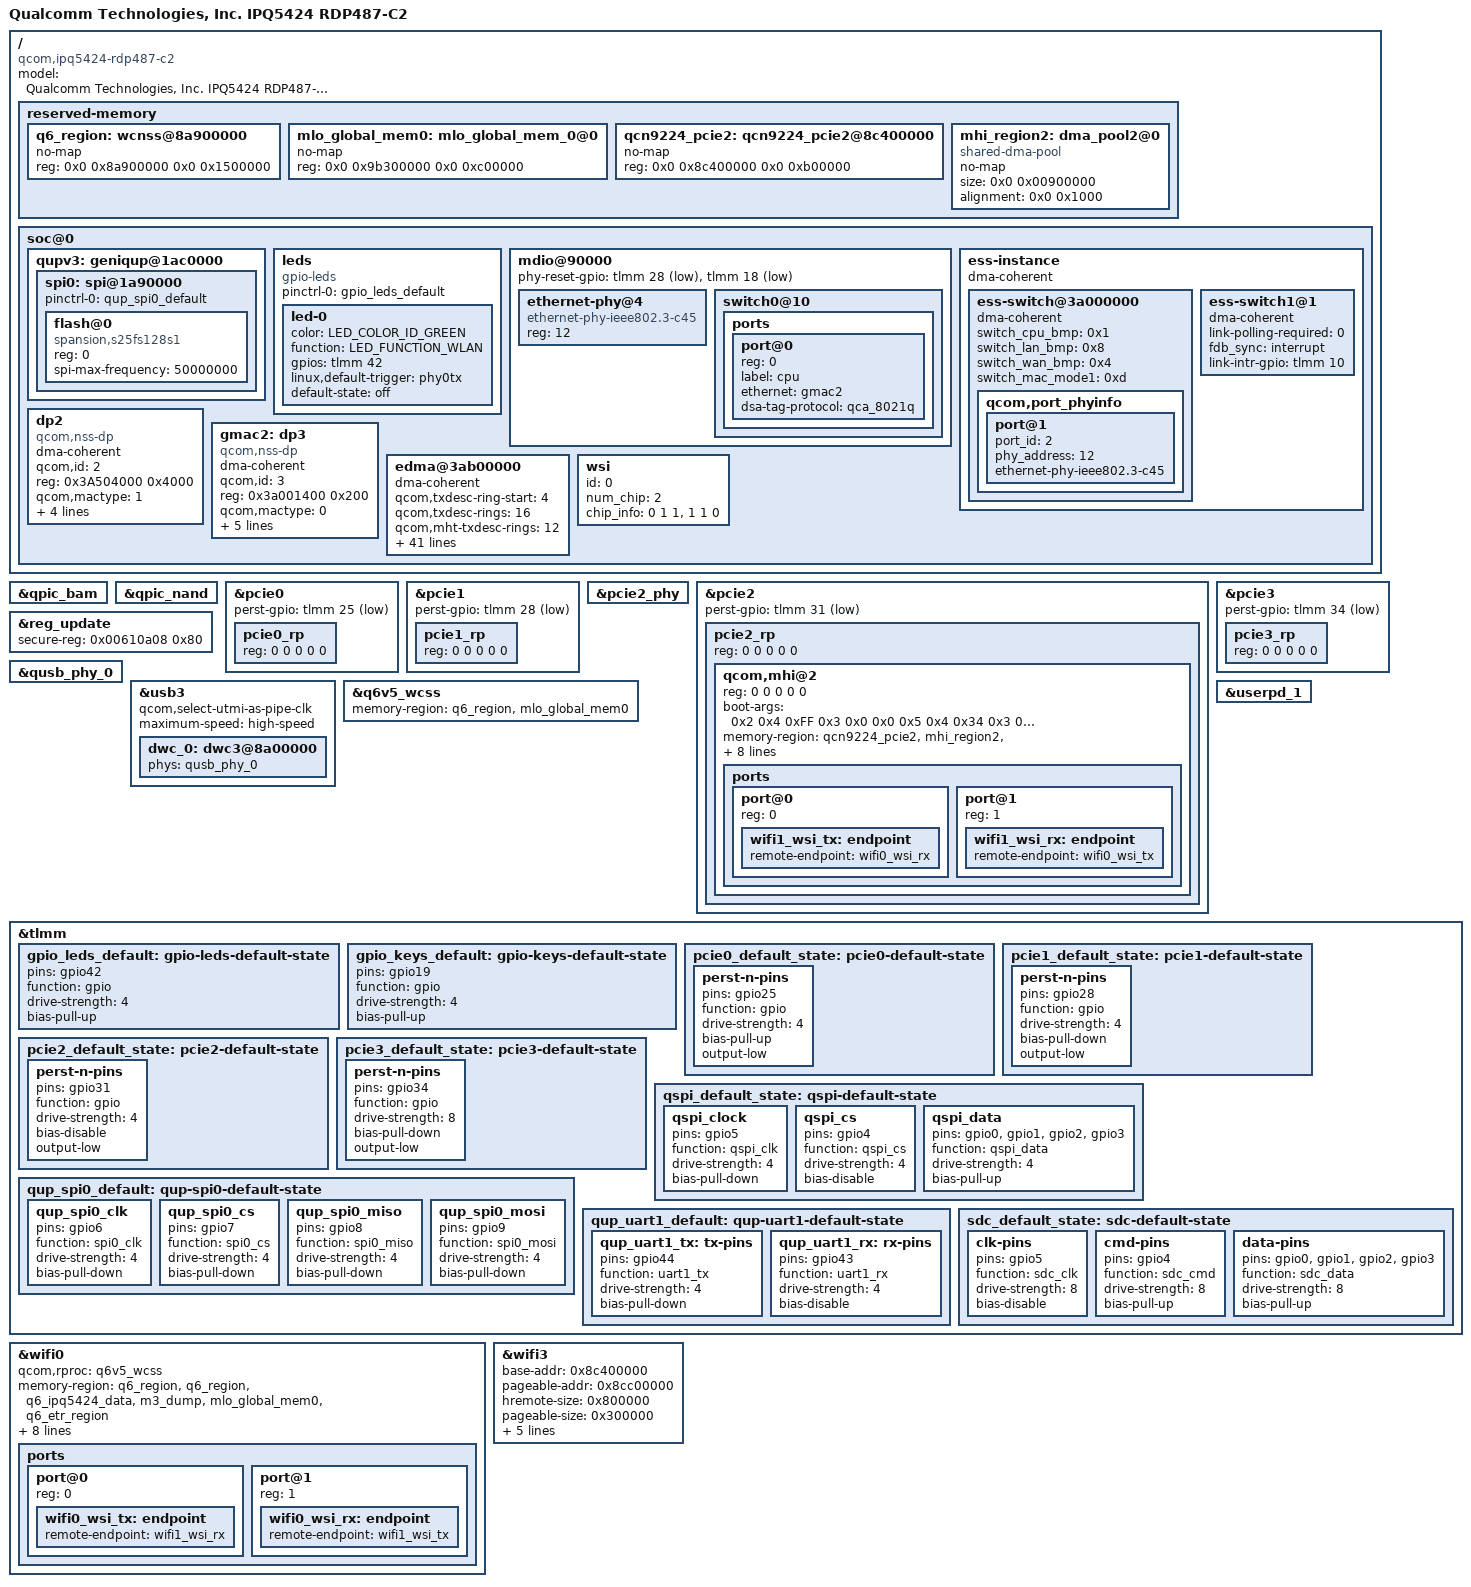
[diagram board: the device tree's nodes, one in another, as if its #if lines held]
// SPDX-License-Identifier: (GPL-2.0+ OR BSD-3-Clause)
/*
 * IPQ5424 RDP487-C2 board device tree source
 *
 * Copyright (c) 2020-2021 The Linux Foundation. All rights reserved.
 * Copyright (c) Qualcomm Technologies, Inc. and/or its subsidiaries.
 */

/dts-v1/;

#include "ipq5424-rdp-common.dtsi"
#if defined(__IPQ_MEM_PROFILE_512_MB__)
#include "ipq5424-512MB-default-memory.dtsi"
#elif !defined(__IPQ_MEM_PROFILE_256_MB__)
#include "ipq5424-default-memory.dtsi"
#endif

/ {
	model = "Qualcomm Technologies, Inc. IPQ5424 RDP487-C2";
	compatible = "qcom,ipq5424-rdp487-c2", "qcom,ipq5424";

#ifdef __IPQ_MEM_PROFILE_256_MB__
	/*                    256MB Profile
	 * +==========+==============+========================+
	 * |         |              |                         |
	 * |  Region | Start Offset |          Size           |
	 * |         |              |                         |
	 * +---------+--------------+-------------------------+
	 * |         |              |                         |
	 * |   WLAN  |              |                         |
	 * |    Q6   |  0x8a900000  |          21MB           |
	 * |         |              |                         |
	 * +---------+--------------+-------------------------+
	 * |         |              |                         |
	 * |  MLO    |  0x8bf00000  |          5MB            |
	 * |         |              |                         |
	 * +---------+--------------+-------------------------+
	 * |         |              |                         |
	 * | QCN9224 |  0x8c400000  |          11MB           |
	 * | PCIE0   |              |                         |
	 * |         |              |                         |
	 * +---------+--------------+-------------------------+
	 * |         |              |                         |
	 * |  MHI0   |    DYNAMIC   |          9MB            |
	 * |         |              |                         |
	 * +==================================================+
	 * |                                                  |
	 * |                                                  |
	 * |                                                  |
	 * |             Rest of memory for Linux             |
	 * |                                                  |
	 * |                                                  |
	 * |                                                  |
	 * +==================================================+
	 */

	reserved-memory {
		#address-cells = <2>;
		#size-cells = <2>;
		ranges;

		q6_region: wcnss@8a900000 {
			no-map;
			reg = <0x0 0x8a900000 0x0 0x1500000>;
		};

		mlo_global_mem0: mlo_global_mem_0@0 {
			no-map;
			reg = <0x0 0x8bf00000 0x0 0x500000>;
		};

		qcn9224_pcie2: qcn9224_pcie2@8c400000 {
			no-map;
			reg = <0x0 0x8c400000 0x0 0xb00000>;
		};

		mhi_region2: dma_pool2@0 {
			compatible = "shared-dma-pool";
			no-map;
			size = <0x0 0x00900000>;
			alignment = <0x0 0x1000>;
		};

	};
#endif

	soc@0 {
		qupv3: geniqup@1ac0000 {

			spi0: spi@1a90000 {
				pinctrl-0 = <&qup_spi0_default>;
				pinctrl-names = "default";
				status = "okay";

				flash@0 {
					compatible = "spansion,s25fs128s1", "jedec,spi-nor";
					#address-cells = <1>;
					#size-cells = <1>;
					reg = <0>;
					spi-max-frequency = <50000000>;
				};
			};
		};

		leds {
			compatible = "gpio-leds";
			pinctrl-0 = <&gpio_leds_default>;
			pinctrl-names = "default";

			led-0 {
				color = <LED_COLOR_ID_GREEN>;
				function = LED_FUNCTION_WLAN;
				gpios = <&tlmm 42 GPIO_ACTIVE_HIGH>;
				linux,default-trigger = "phy0tx";
				default-state = "off";
			};
		};

		mdio@90000 {
			/* GPIO28 is for port 2 QCA81XX PHY */
			/* GPIO18 is for QCA8386 switch */
			phy-reset-gpio = <
				&tlmm 28 GPIO_ACTIVE_LOW
				&tlmm 18 GPIO_ACTIVE_LOW
			>;

			ethernet-phy@4 {
				reg = <12>;
				compatible ="ethernet-phy-ieee802.3-c45";
			};

			switch0@10 {
				ports {
					port@0 {
						reg = <0>;
						label = "cpu";
						ethernet = <&gmac2>;
						dsa-tag-protocol = "qca_8021q";
					};
				};
			};
		};

		ess-instance {
#ifdef __CONFIG_IO_COHERENCY__
			dma-coherent;
#endif
			ess-switch@3a000000 {
#ifdef __CONFIG_IO_COHERENCY__
				dma-coherent;
#endif
				switch_cpu_bmp = <0x1>;  /* cpu port bitmap */
				switch_lan_bmp = <0x8>; /* lan port bitmap */
				switch_wan_bmp = <0x4>; /* wan port bitmap */
				switch_mac_mode1 = <0xd>; /* mac mode for uniphy instance1*/

				qcom,port_phyinfo {
					port@1 {
						port_id = <2>;
						phy_address = <12>;
						ethernet-phy-ieee802.3-c45;
					};
				};
			};

			ess-switch1@1 {
#ifdef __CONFIG_IO_COHERENCY__
				dma-coherent;
#endif
				link-polling-required = <0>;
				fdb_sync = "interrupt";
				link-intr-gpio = <&tlmm 10 GPIO_ACTIVE_HIGH>;
			};
		};

		dp2 {
			device_type = "network";
			compatible = "qcom,nss-dp";
#ifdef __CONFIG_IO_COHERENCY__
			dma-coherent;
#endif
			qcom,id = <2>;
			reg = <0x3A504000 0x4000>;
			qcom,mactype = <1>;
			local-mac-address = [000000000000];
			qcom,phy-mdio-addr = <12>;
			qcom,link-poll = <1>;
			phy-mode = "usxgmii";
		};

		gmac2:dp3 {
			device_type = "network";
			compatible = "qcom,nss-dp";
#ifdef __CONFIG_IO_COHERENCY__
			dma-coherent;
#endif
			qcom,id = <3>;
			reg = <0x3a001400 0x200>;
			qcom,mactype = <0>;
			local-mac-address = [000000000000];
			qcom,mht-dev = <1>;
			qcom,is_switch_connected = <1>;
			phy-mode = "sgmii";
			qcom,ppe-offload-disabled = <1>;
		};

		/* EDMA host driver configuration for the board */
		edma@3ab00000 {
#ifdef __CONFIG_IO_COHERENCY__
			dma-coherent;
#endif
			qcom,txdesc-ring-start = <4>;		/* Tx desc ring start ID */
			qcom,txdesc-rings = <16>;		/* Total number of Tx desc rings to be provisioned */
			qcom,mht-txdesc-rings = <12>;		/* Extra Tx desc rings to be provisioned for MHT SW ports */
			qcom,txcmpl-ring-start = <4>;		/* Tx complete ring start ID */
			qcom,txcmpl-rings = <16>;		/* Total number of Tx complete rings to be provisioned */
			qcom,mht-txcmpl-rings = <12>;		/* Extra Tx complete rings to be provisioned for mht sw ports. */
			qcom,rxfill-ring-start = <4>;		/* Rx fill ring start ID */
			qcom,rxfill-rings = <4>;		/* Total number of Rx fill rings to be provisioned */
			qcom,rxdesc-ring-start = <20>;		/* Rx desc ring start ID */
			qcom,rxdesc-rings = <4>;		/* Total number of Rx desc rings to be provisioned */
			qcom,rx-page-mode = <0>;		/* Rx fill ring page mode */
			qcom,tx-map-priority-level = <1>;	/* Tx priority level per port */
			qcom,rx-map-priority-level = <1>;	/* Rx priority level per core */
			qcom,ppeds-num = <3>;			/* Number of PPEDS nodes */
			/* PPE-DS node format: <Rx-fill Tx-cmpl Rx Tx Queue-base Queue-count> */
			qcom,ppeds-map = <1 1 1 1 32 8>,	/* PPEDS Node #0 ring and queue map */
					<2 2 2 2 40 8>,		/* PPEDS Node #1 ring and queue map */
					<3 3 3 3 48 8>;		/* PPEDS Node #2 ring and queue map */
			qcom,txdesc-map = <4 5 6 7>,		/* Port1 per-core Tx ring map */
					<8 9 10 11>,		/* Port2 per-core Tx ring map */
					<12 13 14 15>,		/* MHT-Port1 per-core Tx ring map */
					<16 17 18 19>,		/* MHT-Port2 per-core Tx ring map */
					<20 21 22 23>,		/* MHT-Port3 per-core Tx ring map */
					<24 25 26 27>,		/* MHT-Port4 per-core Tx ring map */
					<28 29 30 31>;		/* Used only for packets from VP */
			qcom,txdesc-fc-grp-map = <1 2 3 4 5 6>;	/* Per GMAC flow control group map */
			qcom,rxfill-map = <4 5 6 7>;		/* Per-core Rx fill ring map */
			qcom,rxdesc-map = <20 21 22 23>;	/* Per-core Rx desc ring map */
			qcom,rx-queue-start = <0>;		/* Rx queue start */
			qcom,edma_loopback_ring;                /* Enable Loopback ring */
			qcom,num_loopback_rings = <1>;          /* Number of loopback rings */
			qcom,txdesc_loopback_ring_id = <0>;     /* Loopback TX desc ring ID */
			qcom,txcmpl_loopback_ring_id = <0>;     /* Loopback TX cmpl ring ID */
			qcom,rxfill_loopback_ring_id = <0>;     /* Loopback RX fill ring ID */
			qcom,rxdesc_loopback_ring_id = <0>;     /* Loopback RX desc ring ID */
			qcom,loopback_queue_base = <56>;        /* Loopback queue base */
			qcom,loopback_num_queues = <8>;         /* Number of Loopback queues */
			qcom,rx-ring-queue-map = <0 8 16 24>,	/* Priority 0 queues per-core Rx ring map */
						<1 9 17 25>,	/* Priority 1 queues per-core Rx ring map */
						<2 10 18 26>,	/* Priority 2 queues per-core Rx ring map */
						<3 11 19 27>,	/* Priority 3 queues per-core Rx ring map */
						<4 12 20 28>,	/* Priority 4 queues per-core Rx ring map */
						<5 13 21 29>,	/* Priority 5 queues per-core Rx ring map */
						<6 14 22 30>,	/* Priority 6 queues per-core Rx ring map */
						<7 15 23 31>;	/* Priority 7 queues per-core Rx ring map */
			interrupts = <0 286 4>,			/* Tx complete ring id #4 IRQ info */
					<0 287 4>,		/* Tx complete ring id #5 IRQ info */
					<0 288 4>,		/* Tx complete ring id #6 IRQ info */
					<0 289 4>,		/* Tx complete ring id #7 IRQ info */
					<0 290 4>,		/* Tx complete ring id #8 IRQ info */
					<0 291 4>,		/* Tx complete ring id #9 IRQ info */
					<0 292 4>,		/* Tx complete ring id #10 IRQ info */
					<0 293 4>,		/* Tx complete ring id #11 IRQ info */
					<0 294 4>,		/* Tx complete ring id #12 IRQ info */
					<0 295 4>,		/* Tx complete ring id #13 IRQ info */
					<0 296 4>,		/* Tx complete ring id #14 IRQ info */
					<0 297 4>,		/* Tx complete ring id #15 IRQ info */
					<0 298 4>,		/* Tx complete ring id #16 IRQ info */
					<0 299 4>,		/* Tx complete ring id #17 IRQ info */
					<0 300 4>,		/* Tx complete ring id #18 IRQ info */
					<0 301 4>,		/* Tx complete ring id #19 IRQ info */
					<0 270 4>,		/* Rx desc ring id #20 IRQ info */
					<0 271 4>,		/* Rx desc ring id #21 IRQ info */
					<0 272 4>,		/* Rx desc ring id #22 IRQ info */
					<0 273 4>,		/* Rx desc ring id #23 IRQ info */
					<0 314 4>,		/* Misc error IRQ info */
					<0 278 4>,		/* RxFill ring id #4 IRQ info */
					<0 279 4>,		/* RxFill ring id #5 IRQ info */
					<0 280 4>,		/* RxFill ring id #6 IRQ info */
					<0 281 4>,		/* RxFill ring id #7 IRQ info */
					<0 283 4>,		/* PPEDS Node #0(TxComp ring id #1) TxComplete IRQ info */
					<0 251 4>,		/* PPEDS Node #0(Rx Desc ring id #1) Rx Desc IRQ info */
					<0 275 4>,		/* PPEDS Node #0(RxFill Desc ring id #1) Rx Fill IRQ info */
					<0 284 4>,		/* PPEDS Node #1(TxComp ring id #2) TxComplete IRQ info */
					<0 252 4>,		/* PPEDS Node #1(Rx Desc ring id #2) Rx Desc IRQ info */
					<0 276 4>,		/* PPEDS Node #1(RxFill Desc ring id #2) Rx Fill IRQ info */
					<0 285 4>,		/* PPEDS Node #2(TxComp ring id #3) TxComplete IRQ info */
					<0 253 4>,		/* PPEDS Node #2(Rx Desc ring id #3) Rx Desc IRQ info */
					<0 277 4>,		/* PPEDS Node #2(RxFill Desc ring id #3) Rx Fill IRQ info */
					<0 302 4>,		/* MHT port Tx complete ring id #20 IRQ info */
					<0 303 4>,		/* MHT port Tx complete ring id #21 IRQ info */
					<0 304 4>,		/* MHT port Tx complete ring id #22 IRQ info */
					<0 305 4>,		/* MHT port Tx complete ring id #23 IRQ info */
					<0 306 4>,		/* MHT port Tx complete ring id #24 IRQ info */
					<0 307 4>,		/* MHT port Tx complete ring id #25 IRQ info */
					<0 308 4>,		/* MHT port Tx complete ring id #26 IRQ info */
					<0 309 4>,		/* MHT port Tx complete ring id #27 IRQ info */
					<0 310 4>,		/* MHT port Tx complete ring id #28 IRQ info */
					<0 311 4>,		/* MHT port Tx complete ring id #29 IRQ info */
					<0 312 4>,		/* MHT port Tx complete ring id #30 IRQ info */
					<0 313 4>;		/* MHT port Tx complete ring id #31 IRQ info */
		};

		wsi: wsi {
			id = <0>;
			num_chip = <2>;
			chip_info = <0 1 1>,
				    <1 1 0>;
			status = "okay";
		};
	};
};

&qpic_bam {
	status = "okay";
};

&qpic_nand {
	status = "okay";
};

&pcie0 {
	perst-gpio = <&tlmm 25 GPIO_ACTIVE_LOW>;

	pcie0_rp {
		reg = <0 0 0 0 0>;
	};
};

&pcie1 {
	perst-gpio = <&tlmm 28 GPIO_ACTIVE_LOW>;

	pcie1_rp {
		reg = <0 0 0 0 0>;
	};
};

&pcie2_phy {
	status = "okay";
};

&pcie2 {
	status = "okay";
	perst-gpio = <&tlmm 31 GPIO_ACTIVE_LOW>;

	pcie2_rp {
		reg = <0 0 0 0 0>;

		qcom,mhi@2 {
			reg = <0 0 0 0 0>;
			boot-args = <0x2 0x4 0xFF 0x3 0x0 0x0  /* MX Rail, Invalid GPIO, Drive strength 0x3 */
					0x5 0x4 0x34 0x3 0x0 0x16 /* CX Rail, GPIO52, Drive strength 0x3, CPR1_fuse 0x0, CPR0_fuse 0x16 */
					0x0 0x4 0x0 0x0 0x0 0x0>; /* End of arguments */
			memory-region = <&qcn9224_pcie2>, <&mhi_region2>, <&mlo_global_mem0>;
			memory-region-names = "host-ddr-mem", "mhi-region", "mlo-global-mem";
			qcom,early_cal_enabled = "supported";
			qcom,caldata_offset = <0x12000>;
			qcom,board_id = <0x33>;
			qcom,wsi = <&wsi>;
			qcom,wsi_index = <1>;
			ports {
				#address-cells = <1>;
				#size-cells = <0>;

				port@0 {
					reg = <0>;

					wifi1_wsi_tx: endpoint {
						remote-endpoint = <&wifi0_wsi_rx>;
					};
				};

				port@1 {
					reg = <1>;

					wifi1_wsi_rx: endpoint {
						remote-endpoint = <&wifi0_wsi_tx>;
					};
				};
			};
		};
	};
};

&pcie3 {
	perst-gpio = <&tlmm 34 GPIO_ACTIVE_LOW>;

	pcie3_rp {
		reg = <0 0 0 0 0>;
	};
};

&reg_update {
	secure-reg = <0x00610a08 0x80>; /* aggr_noc_pcie2 */
};

&qusb_phy_0 {
	status = "okay";
};

&usb3 {
	status = "okay";
	qcom,select-utmi-as-pipe-clk;
	maximum-speed = "high-speed";

	dwc_0: dwc3@8a00000 {
		phys = <&qusb_phy_0>;
		phy-names = "usb2-phy";
	};
};

&q6v5_wcss {
#ifdef __IPQ_MEM_PROFILE_256_MB__
	memory-region = <&q6_region>,
			<&mlo_global_mem0>;
#endif
	status = "okay";
};

#if !defined(__RPROC_DISABLE_MPD_SUPPORT__)
&userpd_1 {
	status = "okay";
};
#endif

&tlmm {
	gpio_leds_default: gpio-leds-default-state {
		pins = "gpio42";
		function = "gpio";
		drive-strength = <4>;
		bias-pull-up;
	};

	gpio_keys_default: gpio-keys-default-state {
		pins = "gpio19";
		function = "gpio";
		drive-strength = <4>;
		bias-pull-up;
	};

	pcie0_default_state: pcie0-default-state {
		perst-n-pins {
			pins = "gpio25";
			function = "gpio";
			drive-strength = <4>;
			bias-pull-up;
			output-low;
		};
	};

	pcie1_default_state: pcie1-default-state {
		perst-n-pins {
			pins = "gpio28";
			function = "gpio";
			drive-strength = <4>;
			bias-pull-down;
			output-low;
		};
	};

	pcie2_default_state: pcie2-default-state {
		perst-n-pins {
			pins = "gpio31";
			function = "gpio";
			drive-strength = <4>;
			bias-disable;
			output-low;
		};
	};

	pcie3_default_state: pcie3-default-state {
		perst-n-pins {
			pins = "gpio34";
			function = "gpio";
			drive-strength = <8>;
			bias-pull-down;
			output-low;
		};
	};

	qspi_default_state: qspi-default-state {
		qspi_clock {
			pins = "gpio5";
			function = "qspi_clk";
			drive-strength = <4>;
			bias-pull-down;
		};

		qspi_cs {
			pins = "gpio4";
			function = "qspi_cs";
			drive-strength = <4>;
			bias-disable;
		};

		qspi_data {
			pins = "gpio0", "gpio1", "gpio2", "gpio3";
			function = "qspi_data";
			drive-strength = <4>;
			bias-pull-up;
		};
	};

	qup_spi0_default: qup-spi0-default-state {
		qup_spi0_clk {
			pins = "gpio6";
			function = "spi0_clk";
			drive-strength = <4>;
			bias-pull-down;
		};

		qup_spi0_cs {
			pins = "gpio7";
			function = "spi0_cs";
			drive-strength = <4>;
			bias-pull-down;
		};

		qup_spi0_miso {
			pins = "gpio8";
			function = "spi0_miso";
			drive-strength = <4>;
			bias-pull-down;
		};

		qup_spi0_mosi {
			pins = "gpio9";
			function = "spi0_mosi";
			drive-strength = <4>;
			bias-pull-down;
		};
	};

	qup_uart1_default: qup-uart1-default-state {
		qup_uart1_tx: tx-pins {
			pins = "gpio44";
			function = "uart1_tx";
			drive-strength = <4>;
			bias-pull-down;
		};

		qup_uart1_rx: rx-pins {
			pins = "gpio43";
			function = "uart1_rx";
			drive-strength = <4>;
			bias-disable;
		};
	};

	sdc_default_state: sdc-default-state {
		clk-pins {
			pins = "gpio5";
			function = "sdc_clk";
			drive-strength = <8>;
			bias-disable;
		};

		cmd-pins {
			pins = "gpio4";
			function = "sdc_cmd";
			drive-strength = <8>;
			bias-pull-up;
		};

		data-pins {
			pins = "gpio0", "gpio1", "gpio2", "gpio3";
			function = "sdc_data";
			drive-strength = <8>;
			bias-pull-up;
		};
	};

};

&qcn9224_pcie2 {
	status = "okay";
};

#if defined(__MHI_BUS_RESERVED_DMA_POOL__)
&mhi_region2 {
	status = "okay";
};
#endif

#if !defined(__IPQ_MEM_PROFILE_256_MB__)
&mlo_global_mem0 {
	reg = <0x0 0x9b300000 0x0 0xc00000>;
	status = "okay";
};
#endif

&wifi0 {
	qcom,rproc = <&q6v5_wcss>;
#if !defined(__IPQ_MEM_PROFILE_256_MB__)
	memory-region = <&q6_region>, <&q6_region>,<&q6_ipq5424_data>, <&m3_dump>,
			<&mlo_global_mem0>, <&q6_etr_region>;
	memory-region-names = "q6-region", "q6-region-1", "host-ddr-mem", "m3-dump",
			"mlo-global-mem", "q6-etr-dump";
#else
	memory-region = <&q6_region>, <&q6_region>, <&mlo_global_mem0>;
	memory-region-names = "q6-region", "q6-region-1", "mlo-global-mem";
#endif
	qcom,wsi = <&wsi>;
	qcom,wsi_index = <0>;
	qcom,board_id = <0x14>;
	hw_link_id = <0 0>;
	status = "okay";
	qcom,wsi-controller;
	ports {
		#address-cells = <1>;
		#size-cells = <0>;

		port@0 {
			reg = <0>;

			wifi0_wsi_tx: endpoint {
				remote-endpoint = <&wifi1_wsi_rx>;
			};
		};

		port@1 {
			reg = <1>;

			wifi0_wsi_rx: endpoint {
				remote-endpoint = <&wifi1_wsi_tx>;
			};
		};
	};
};

&wifi3 {
#ifdef __IPQ_MEM_PROFILE_256_MB__
	/* qcn9224 tgt-mem-mode=2 layout - 11MB
	 * +=========+==============+=========+
	 * |  Region | Start Offset |   Size  |
	 * +---------+--------------+---------+
	 * | HREMOTE |  0x8c400000  |   8MB   |
	 * +---------+--------------+---------+
	 * |Pageable |  0x8cc00000  |   3MB   |
	 * +==================================+
	 */
	base-addr = <0x8c400000>;
	pageable-addr = <0x8cc00000>;
	hremote-size = <0x800000>;
	pageable-size = <0x300000>;
	caldb-size = <0>;
	tgt-mem-mode = <0x2>;
#endif
	hremote_node = <&qcn9224_pcie2>;
	board_id = <0x33>;
	hw_link_id = <1 0>;
	status = "okay";
};
